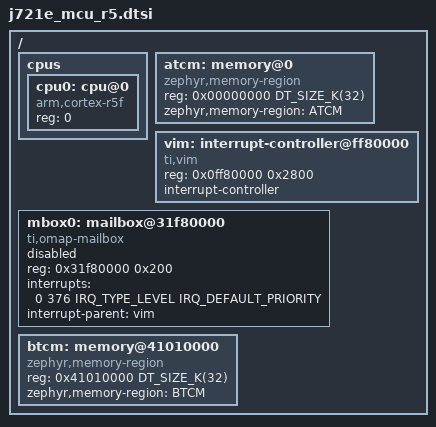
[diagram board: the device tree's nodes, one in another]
/*
 * Copyright (c) 2026 Dhruv Menon <dhruvmenon1104@gmail.com>
 *
 * SPDX-License-Identifier: Apache-2.0
 */

#include <mem.h>
#include <freq.h>
#include <arm/armv7-r.dtsi>
#include <zephyr/dt-bindings/interrupt-controller/ti-vim.h>
#include <ti/j721e_mcu.dtsi>

/ {
	#address-cells = <1>;
	#size-cells = <1>;

	cpus {
		#address-cells = <1>;
		#size-cells = <0>;

		cpu0: cpu@0 {
			compatible = "arm,cortex-r5f";
			reg = <0>;
			device_type = "cpu";
		};
	};

	atcm: memory@0 {
		compatible = "zephyr,memory-region", "mmio-sram";
		reg = <0x00000000 DT_SIZE_K(32)>;
		device_type = "memory";
		zephyr,memory-region = "ATCM";
	};

	vim: interrupt-controller@ff80000 {
		compatible = "ti,vim";
		reg = <0x0ff80000 0x2800>;
		#address-cells = <1>;
		interrupt-controller;
		#interrupt-cells = <4>; /* {IRQ/FIQ, IRQ_NUM, IRQ_TYPE, IRQ_PRIO} */
		status = "okay";
	};

	/* MAIN NAVSS mailbox cluster 0 (Linux mailbox0_cluster0) */
	mbox0: mailbox@31f80000 {
		compatible = "ti,omap-mailbox";
		reg = <0x31f80000 0x200>;
		/* NAVSS0_INTR_ROUTER_0 out to MCU R5F VIM 376; TISCI irq_dsts */
		interrupts = <0 376 IRQ_TYPE_LEVEL IRQ_DEFAULT_PRIORITY>;
		interrupt-parent = <&vim>;
		#mbox-cells = <1>;
		status = "disabled";
	};

	btcm: memory@41010000 {
		compatible = "zephyr,memory-region", "mmio-sram";
		reg = <0x41010000 DT_SIZE_K(32)>;
		device_type = "memory";
		zephyr,memory-region = "BTCM";
	};
};
